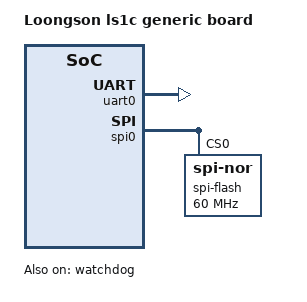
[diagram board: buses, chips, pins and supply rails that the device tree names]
// SPDX-License-Identifier: GPL-2.0

/dts-v1/;

#include "loongson,ls1c.dtsi"

/ {
	compatible = "loongson,ls1c-generic", "loongson,ls1c-soc";
	model = "Loongson ls1c generic board";

	chosen {
		stdout-path = &uart0;
	};
};

&uart0 {
	status = "okay";
};

&watchdog {
	status = "okay";
};

&spi0 {
	status = "okay";

	spi-flash@0 {
		#address-cells = <1>;
		#size-cells = <1>;
		compatible = "jedec,spi-nor";
		spi-max-frequency = <60000000>;
		reg = <0>;
	};
};
